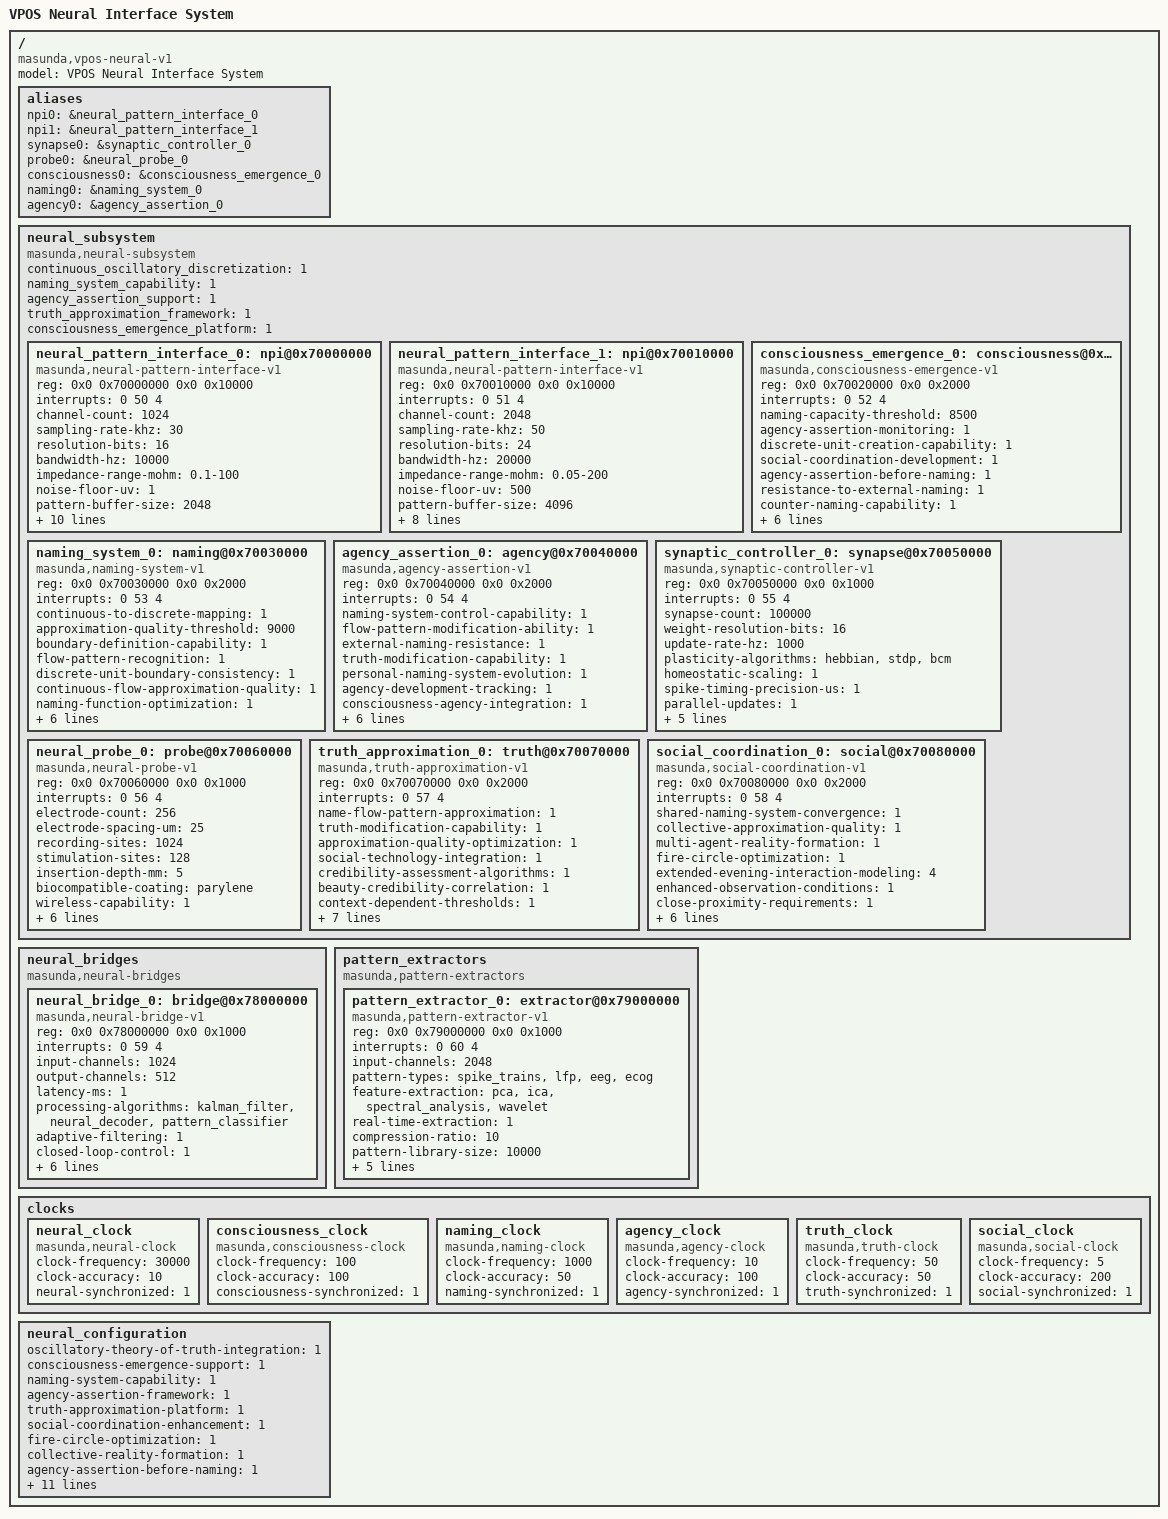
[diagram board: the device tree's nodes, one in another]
/*
 * VPOS Neural Interfaces Device Tree Source
 * Masunda Temporal Coordinate Navigator - Neural Hardware Definition
 * 
 * This device tree defines neural pattern interfaces, consciousness emergence
 * systems, naming system hardware, and agency assertion mechanisms
 */

/dts-v1/;

/ {
    model = "VPOS Neural Interface System";
    compatible = "masunda,vpos-neural-v1";
    
    #address-cells = <2>;
    #size-cells = <2>;

    aliases {
        npi0 = &neural_pattern_interface_0;
        npi1 = &neural_pattern_interface_1;
        synapse0 = &synaptic_controller_0;
        probe0 = &neural_probe_0;
        consciousness0 = &consciousness_emergence_0;
        naming0 = &naming_system_0;
        agency0 = &agency_assertion_0;
    };

    neural_subsystem {
        compatible = "masunda,neural-subsystem";
        status = "okay";
        
        /* Oscillatory theory of truth integration */
        continuous_oscillatory_discretization = <1>;
        naming_system_capability = <1>;
        agency_assertion_support = <1>;
        truth_approximation_framework = <1>;
        consciousness_emergence_platform = <1>;
        
        neural_pattern_interface_0: npi@0x70000000 {
            compatible = "masunda,neural-pattern-interface-v1";
            reg = <0x0 0x70000000 0x0 0x10000>;
            interrupts = <0 50 4>;
            status = "okay";
            
            /* NPI properties */
            channel-count = <1024>;
            sampling-rate-khz = <30>;
            resolution-bits = <16>;
            bandwidth-hz = <10000>;
            impedance-range-mohm = "0.1-100";
            noise-floor-uv = <1>;
            pattern-buffer-size = <2048>;
            real-time-processing = <1>;
            
            /* Naming system interface properties */
            continuous-pattern-discretization = <1>;
            discrete-unit-creation = <1>;
            pattern-naming-capability = <1>;
            flow-pattern-recognition = <1>;
            
            /* Search-identification equivalence */
            pattern-matching-optimization = <1>;
            search-algorithm-efficiency = <1>;
            identification-accuracy-enhancement = <1>;
            computational-cost-minimization = <1>;
            
            clocks = <&neural_clock>;
            clock-names = "neural_ref";
        };
        
        neural_pattern_interface_1: npi@0x70010000 {
            compatible = "masunda,neural-pattern-interface-v1";
            reg = <0x0 0x70010000 0x0 0x10000>;
            interrupts = <0 51 4>;
            status = "okay";
            
            /* Enhanced NPI properties */
            channel-count = <2048>;
            sampling-rate-khz = <50>;
            resolution-bits = <24>;
            bandwidth-hz = <20000>;
            impedance-range-mohm = "0.05-200";
            noise-floor-uv = <500>; /* 0.5 * 1000 */
            pattern-buffer-size = <4096>;
            real-time-processing = <1>;
            
            /* Advanced naming system properties */
            continuous-pattern-discretization = <1>;
            discrete-unit-creation = <1>;
            pattern-naming-capability = <1>;
            flow-pattern-recognition = <1>;
            agency-pattern-recognition = <1>;
            truth-approximation-pattern-processing = <1>;
            
            clocks = <&neural_clock>;
            clock-names = "neural_ref";
        };
        
        consciousness_emergence_0: consciousness@0x70020000 {
            compatible = "masunda,consciousness-emergence-v1";
            reg = <0x0 0x70020000 0x0 0x2000>;
            interrupts = <0 52 4>;
            status = "okay";
            
            /* Consciousness emergence properties */
            naming-capacity-threshold = <8500>; /* 0.85 * 10000 */
            agency-assertion-monitoring = <1>;
            discrete-unit-creation-capability = <1>;
            social-coordination-development = <1>;
            
            /* Agency-first principle implementation */
            agency-assertion-before-naming = <1>;
            resistance-to-external-naming = <1>;
            counter-naming-capability = <1>;
            control-over-naming-patterns = <1>;
            
            /* Consciousness development tracking */
            consciousness-emergence-pattern-validation = <1>;
            agency-first-principle-compliance = <1>;
            naming-system-sophistication-tracking = <1>;
            temporal-sequence-consistency = <1>;
            
            clocks = <&consciousness_clock>;
            clock-names = "consciousness_ref";
        };
        
        naming_system_0: naming@0x70030000 {
            compatible = "masunda,naming-system-v1";
            reg = <0x0 0x70030000 0x0 0x2000>;
            interrupts = <0 53 4>;
            status = "okay";
            
            /* Naming system properties */
            continuous-to-discrete-mapping = <1>;
            approximation-quality-threshold = <9000>; /* 0.9 * 10000 */
            boundary-definition-capability = <1>;
            flow-pattern-recognition = <1>;
            
            /* Core naming functions */
            discrete-unit-boundary-consistency = <1>;
            continuous-flow-approximation-quality = <1>;
            naming-function-optimization = <1>;
            pattern-recognition-accuracy = <1>;
            
            /* Social naming integration */
            shared-naming-system-convergence = <1>;
            inter-agent-naming-consistency = <1>;
            naming-negotiation-protocols = <1>;
            collective-reality-formation-integration = <1>;
            
            clocks = <&naming_clock>;
            clock-names = "naming_ref";
        };
        
        agency_assertion_0: agency@0x70040000 {
            compatible = "masunda,agency-assertion-v1";
            reg = <0x0 0x70040000 0x0 0x2000>;
            interrupts = <0 54 4>;
            status = "okay";
            
            /* Agency assertion properties */
            naming-system-control-capability = <1>;
            flow-pattern-modification-ability = <1>;
            external-naming-resistance = <1>;
            truth-modification-capability = <1>;
            
            /* Individual agency development */
            personal-naming-system-evolution = <1>;
            agency-development-tracking = <1>;
            consciousness-agency-integration = <1>;
            free-will-within-constraints = <1>;
            
            /* Agency integrity monitoring */
            agency-assertion-strength-measurement = <1>;
            naming-system-control-verification = <1>;
            reality-modification-capability-checking = <1>;
            collective-agency-coordination-integrity = <1>;
            
            clocks = <&agency_clock>;
            clock-names = "agency_ref";
        };
        
        synaptic_controller_0: synapse@0x70050000 {
            compatible = "masunda,synaptic-controller-v1";
            reg = <0x0 0x70050000 0x0 0x1000>;
            interrupts = <0 55 4>;
            status = "okay";
            
            /* Synaptic properties */
            synapse-count = <100000>;
            weight-resolution-bits = <16>;
            update-rate-hz = <1000>;
            plasticity-algorithms = "hebbian", "stdp", "bcm";
            homeostatic-scaling = <1>;
            spike-timing-precision-us = <1>;
            parallel-updates = <1>;
            
            /* Consciousness synaptic integration */
            naming-system-synaptic-encoding = <1>;
            agency-assertion-synaptic-pathways = <1>;
            discrete-unit-synaptic-representation = <1>;
            approximation-synaptic-optimization = <1>;
            
            clocks = <&neural_clock>;
            clock-names = "synaptic_ref";
        };
        
        neural_probe_0: probe@0x70060000 {
            compatible = "masunda,neural-probe-v1";
            reg = <0x0 0x70060000 0x0 0x1000>;
            interrupts = <0 56 4>;
            status = "okay";
            
            /* Probe properties */
            electrode-count = <256>;
            electrode-spacing-um = <25>;
            recording-sites = <1024>;
            stimulation-sites = <128>;
            insertion-depth-mm = <5>;
            biocompatible-coating = "parylene";
            wireless-capability = <1>;
            power-consumption-mw = <10>;
            
            /* Consciousness probing capabilities */
            naming-system-neural-probing = <1>;
            agency-assertion-detection = <1>;
            discrete-unit-creation-monitoring = <1>;
            truth-approximation-neural-correlation = <1>;
            
            clocks = <&neural_clock>;
            clock-names = "probe_ref";
        };
        
        truth_approximation_0: truth@0x70070000 {
            compatible = "masunda,truth-approximation-v1";
            reg = <0x0 0x70070000 0x0 0x2000>;
            interrupts = <0 57 4>;
            status = "okay";
            
            /* Truth approximation properties */
            name-flow-pattern-approximation = <1>;
            truth-modification-capability = <1>;
            approximation-quality-optimization = <1>;
            social-technology-integration = <1>;
            
            /* Fire circle truth systems */
            credibility-assessment-algorithms = <1>;
            beauty-credibility-correlation = <1>;
            context-dependent-thresholds = <1>;
            strategic-truth-modification = <1>;
            
            /* Game-theoretic truth processing */
            facial-attractiveness-credibility-integration = <1>;
            context-dependent-threshold-adaptation = <1>;
            social-signaling-processing = <1>;
            strategic-modification-capability = <1>;
            
            clocks = <&truth_clock>;
            clock-names = "truth_ref";
        };
        
        social_coordination_0: social@0x70080000 {
            compatible = "masunda,social-coordination-v1";
            reg = <0x0 0x70080000 0x0 0x2000>;
            interrupts = <0 58 4>;
            status = "okay";
            
            /* Social coordination properties */
            shared-naming-system-convergence = <1>;
            collective-approximation-quality = <1>;
            multi-agent-reality-formation = <1>;
            fire-circle-optimization = <1>;
            
            /* Fire circle environment simulation */
            extended-evening-interaction-modeling = <4>; /* 4-6 hours */
            enhanced-observation-conditions = <1>;
            close-proximity-requirements = <1>;
            consistent-grouping-patterns = <1>;
            
            /* Collective reality formation */
            multi-agent-naming-convergence = <1>;
            shared-reality-consistency = <1>;
            collective-approximation-stability = <1>;
            social-coordination-verification = <1>;
            
            clocks = <&social_clock>;
            clock-names = "social_ref";
        };
    };
    
    neural_bridges {
        compatible = "masunda,neural-bridges";
        status = "okay";
        
        neural_bridge_0: bridge@0x78000000 {
            compatible = "masunda,neural-bridge-v1";
            reg = <0x0 0x78000000 0x0 0x1000>;
            interrupts = <0 59 4>;
            status = "okay";
            
            /* Bridge properties */
            input-channels = <1024>;
            output-channels = <512>;
            latency-ms = <1>;
            processing-algorithms = "kalman_filter", "neural_decoder", "pattern_classifier";
            adaptive-filtering = <1>;
            closed-loop-control = <1>;
            bi-directional = <1>;
            
            /* Naming system bridging */
            discrete-unit-transfer = <1>;
            flow-pattern-communication = <1>;
            agency-assertion-signaling = <1>;
            truth-approximation-sharing = <1>;
            
            clocks = <&neural_clock>;
            clock-names = "bridge_ref";
        };
    };
    
    pattern_extractors {
        compatible = "masunda,pattern-extractors";
        status = "okay";
        
        pattern_extractor_0: extractor@0x79000000 {
            compatible = "masunda,pattern-extractor-v1";
            reg = <0x0 0x79000000 0x0 0x1000>;
            interrupts = <0 60 4>;
            status = "okay";
            
            /* Extractor properties */
            input-channels = <2048>;
            pattern-types = "spike_trains", "lfp", "eeg", "ecog";
            feature-extraction = "pca", "ica", "spectral_analysis", "wavelet";
            real-time-extraction = <1>;
            compression-ratio = <10>;
            pattern-library-size = <10000>;
            
            /* Consciousness pattern extraction */
            naming-pattern-extraction = <1>;
            agency-assertion-pattern-detection = <1>;
            discrete-unit-pattern-identification = <1>;
            truth-approximation-pattern-analysis = <1>;
            
            clocks = <&neural_clock>;
            clock-names = "extractor_ref";
        };
    };
    
    clocks {
        neural_clock: neural_clock {
            compatible = "masunda,neural-clock";
            #clock-cells = <0>;
            clock-frequency = <30000>; /* 30 kHz sampling */
            clock-accuracy = <10>; /* 10 ppm */
            neural-synchronized = <1>;
        };
        
        consciousness_clock: consciousness_clock {
            compatible = "masunda,consciousness-clock";
            #clock-cells = <0>;
            clock-frequency = <100>; /* 100 Hz consciousness monitoring */
            clock-accuracy = <100>; /* 100 ppm */
            consciousness-synchronized = <1>;
        };
        
        naming_clock: naming_clock {
            compatible = "masunda,naming-clock";
            #clock-cells = <0>;
            clock-frequency = <1000>; /* 1 kHz naming operations */
            clock-accuracy = <50>; /* 50 ppm */
            naming-synchronized = <1>;
        };
        
        agency_clock: agency_clock {
            compatible = "masunda,agency-clock";
            #clock-cells = <0>;
            clock-frequency = <10>; /* 10 Hz agency assertion monitoring */
            clock-accuracy = <100>; /* 100 ppm */
            agency-synchronized = <1>;
        };
        
        truth_clock: truth_clock {
            compatible = "masunda,truth-clock";
            #clock-cells = <0>;
            clock-frequency = <50>; /* 50 Hz truth approximation */
            clock-accuracy = <50>; /* 50 ppm */
            truth-synchronized = <1>;
        };
        
        social_clock: social_clock {
            compatible = "masunda,social-clock";
            #clock-cells = <0>;
            clock-frequency = <5>; /* 5 Hz social coordination */
            clock-accuracy = <200>; /* 200 ppm */
            social-synchronized = <1>;
        };
    };
    
    neural_configuration {
        /* Global neural system configuration */
        oscillatory-theory-of-truth-integration = <1>;
        consciousness-emergence-support = <1>;
        naming-system-capability = <1>;
        agency-assertion-framework = <1>;
        truth-approximation-platform = <1>;
        social-coordination-enhancement = <1>;
        fire-circle-optimization = <1>;
        collective-reality-formation = <1>;
        
        /* Agency-first principle enforcement */
        agency-assertion-before-naming = <1>;
        resistance-to-external-naming = <1>;
        counter-naming-capability = <1>;
        control-over-naming-patterns = <1>;
        
        /* Search-identification equivalence optimization */
        pattern-matching-optimization = <1>;
        search-algorithm-efficiency = <1>;
        identification-accuracy-enhancement = <1>;
        computational-cost-minimization = <1>;
        
        /* Masunda temporal coordinate navigator */
        consciousness-temporal-navigation = <1>;
        naming-system-temporal-integration = <1>;
        agency-assertion-temporal-control = <1>;
        truth-approximation-temporal-framework = <1>;
    };
}; 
